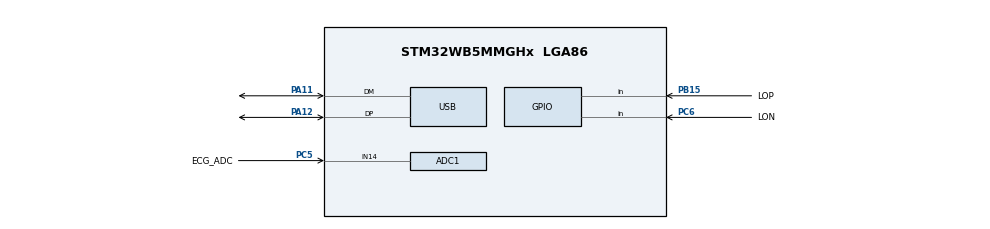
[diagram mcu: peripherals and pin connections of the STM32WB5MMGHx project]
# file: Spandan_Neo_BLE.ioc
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ADC1.Channel-5\#ChannelRegularConversion=ADC_CHANNEL_14
ADC1.NbrOfConversionFlag=1
ADC1.OffsetNumber-5\#ChannelRegularConversion=ADC_OFFSET_NONE
ADC1.Rank-5\#ChannelRegularConversion=1
ADC1.SamplingTime-5\#ChannelRegularConversion=ADC_SAMPLETIME_2CYCLES_5
ADC1.master=1
Mcu.Family=STM32WB
Mcu.Name=STM32WB5MMGHx
Mcu.Package=LGA86
NVIC.HSEM_IRQn=true\:0\:0\:false\:false\:true\:false\:true\:true
NVIC.IPCC_C1_RX_IRQn=true\:0\:0\:false\:false\:true\:true\:true\:true
NVIC.IPCC_C1_TX_IRQn=true\:0\:0\:false\:false\:true\:true\:true\:true
NVIC.PriorityGroup=NVIC_PRIORITYGROUP_4
NVIC.RTC_WKUP_IRQn=true\:0\:0\:false\:false\:true\:true\:true\:true
NVIC.TIM1_UP_TIM16_IRQn=true\:0\:0\:false\:false\:true\:true\:true\:true
NVIC.USB_LP_IRQn=true\:0\:0\:false\:false\:true\:false\:true\:true
PA11.Mode=Device
PA11.Signal=USB_DM
PA12.Mode=Device
PA12.Signal=USB_DP
PA13.Mode=Serial_Wire
PA13.Signal=SYS_JTMS-SWDIO
PA14.Mode=Serial_Wire
PA14.Signal=SYS_JTCK-SWCLK
PB15.GPIO_Label=LOP
PB15.Signal=GPIO_Input
PC5.GPIO_Label=ECG_ADC
PC5.Signal=ADCx_IN14
PC6.GPIO_Label=LON
PC6.Signal=GPIO_Input
ProjectManager.HeapSize=0x400
ProjectManager.StackSize=0x400
ProjectManager.TargetToolchain=STM32CubeIDE
RCC.ADCFreq_Value=48000000
RCC.AHB2CLKDivider=RCC_SYSCLK_DIV2
RCC.AHBFreq_Value=64000000
RCC.APB1Freq_Value=64000000
RCC.APB1TimFreq_Value=64000000
RCC.APB2Freq_Value=64000000
RCC.APB2TimFreq_Value=64000000
RCC.APB3Freq_Value=16000000
RCC.Cortex2_Div=SYSTICK_CLKSOURCE_HCLK_DIV8
RCC.CortexFreq_Value=64000000
RCC.HCLKFreq_Value=64000000
RCC.HSE_VALUE=32000000
RCC.HSI48_VALUE=48000000
RCC.HSI_VALUE=16000000
RCC.PLLN=32
RCC.PLLSAI1N=24
RCC.RTCClockSelection=RCC_RTCCLKSOURCE_LSE
RCC.SYSCLKFreq_VALUE=64000000
RCC.SYSCLKSource=RCC_SYSCLKSOURCE_PLLCLK
RCC.USBFreq_Value=48000000
RCC.VCOOutputFreq_Value=128000000
SH.ADCx_IN14.0=ADC1_IN14,IN14-Single-Ended
STM32_WPAN.CFG_GAP_DEVICE_NAME=SPANDAN_PATCH
STM32_WPAN.CFG_GAP_DEVICE_NAME_LENGTH=13
STM32_WPAN.CUSTOM_P2P_SERVER=Disabled
STM32_WPAN.CUSTOM_TEMPLATE=Enabled
STM32_WPAN.INCLUDE_AD_TYPE_COMPLETE_LOCAL_NAME=1
STM32_WPAN.NUMBER_OF_SERVICES=1
STM32_WPAN.SERVICE1_CHAR1_GATT_NOTIFY_READ_REQ_AND_WAIT_FOR_APPL_RESP=\ 
STM32_WPAN.SERVICE1_CHAR1_GATT_NOTIFY_WRITE_REQ_AND_WAIT_FOR_APPL_RESP=\ 
STM32_WPAN.SERVICE1_CHAR1_LENGTH_CHARACTERISTIC=CHAR_VALUE_LEN_VARIABLE
STM32_WPAN.SERVICE1_CHAR1_LONG_NAME=CHAR_WR
STM32_WPAN.SERVICE1_CHAR1_PROP_WRITE=CHAR_PROP_WRITE
STM32_WPAN.SERVICE1_CHAR1_SHORT_NAME=CHAR_WR
STM32_WPAN.SERVICE1_CHAR2_LENGTH_CHARACTERISTIC=CHAR_VALUE_LEN_VARIABLE
STM32_WPAN.SERVICE1_CHAR2_LONG_NAME=myCharNotify
STM32_WPAN.SERVICE1_CHAR2_PROP_NOTIFY=CHAR_PROP_NOTIFY
STM32_WPAN.SERVICE1_CHAR2_SHORT_NAME=myCharNotify
STM32_WPAN.SERVICE1_LONG_NAME=SPANDAN_PATCH
STM32_WPAN.SERVICE1_NUMBER_OF_CHARACTERISTICS=2
STM32_WPAN.SERVICE1_SHORT_NAME=SPANDAN_PATCH
USB_DEVICE.CLASS_NAME_FS=CDC
USB_DEVICE.VirtualMode=Cdc
USB_DEVICE.VirtualModeFS=Cdc_FS
VP_HSEM_VS_HSEM.Mode=HSEM_Activate
VP_IPCC_VS_IPCC.Mode=IPCC_Activate
VP_MEMORYMAP_VS_MEMORYMAP.Mode=CurAppReg
VP_RCC_V_OSC32_IN.Mode=LSE-External-Clock-Source
VP_RCC_V_OSC_IN.Mode=HSE-External-Clock-Source
VP_RF_VS_RF.Mode=RF_Activate
VP_RTC_VS_RTC_Activate.Mode=RTC_Enabled
VP_RTC_VS_RTC_Calendar.Mode=RTC_Calendar
VP_RTC_VS_RTC_WakeUp_intern.Mode=WakeUp
VP_SEQUENCER_VS_SEQUENCER.Mode=SEQUENCER_Enabled
VP_STM32_WPAN_VS_BLE_HOST.Mode=STM32_WPAN_Enabled
VP_TIM16_VS_ClockSourceINT.Mode=Enable_Timer
VP_TINY_LPM_VS_TINY_LPM.Mode=TINY_LPM_Enabled
VP_USB_DEVICE_VS_USB_DEVICE_CDC_FS.Mode=CDC_FS
board=STM32WB5MM-DK

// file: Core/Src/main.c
/* USER CODE BEGIN Header */
/**
  ******************************************************************************
  * @file           : main.c
  * @brief          : Main program body
  ******************************************************************************
  * @attention
  *
  * Copyright (c) 2026 STMicroelectronics.
  * All rights reserved.
  *
  * This software is licensed under terms that can be found in the LICENSE file
  * in the root directory of this software component.
  * If no LICENSE file comes with this software, it is provided AS-IS.
  *
  ******************************************************************************
  */
/* USER CODE END Header */
#include "main.h"
#include "adc.h"
#include "ipcc.h"
#include "rf.h"
#include "rtc.h"
#include "tim.h"
#include "usb_device.h"
#include "gpio.h"

/* USER CODE BEGIN PV */
extern void Main_task(void);
extern void Main_Init(void);
/* USER CODE END PV */

void SystemClock_Config(void);
void PeriphCommonClock_Config(void);

int main(void)
{

  /* MCU Configuration--------------------------------------------------------*/

  /* Reset of all peripherals, Initializes the Flash interface and the Systick. */

	HAL_Init();
  /* Config code for STM32_WPAN (HSE Tuning must be done before system clock configuration) */
  MX_APPE_Config();

  /* Configure the system clock */
  SystemClock_Config();

  /* Configure the peripherals common clocks */
  PeriphCommonClock_Config();

  /* IPCC initialisation */
  MX_IPCC_Init();

  /* Initialize all configured peripherals */
  MX_GPIO_Init();
  MX_ADC1_Init();
  MX_RTC_Init();
  MX_USB_Device_Init();
  MX_TIM16_Init();
  MX_RF_Init();
  /* USER CODE BEGIN 2 */
  Main_Init();

	#ifdef USB_Mode_Active

	  Main_task();

	#endif

  /* USER CODE END 2 */

  /* Init code for STM32_WPAN */
  MX_APPE_Init();

  /* Infinite loop */
  while (1)
  {
    MX_APPE_Process();

  }
}

void SystemClock_Config(void)
{
  RCC_OscInitTypeDef RCC_OscInitStruct = {0};
  RCC_ClkInitTypeDef RCC_ClkInitStruct = {0};

  /** Configure LSE Drive Capability
  */
  HAL_PWR_EnableBkUpAccess();
  __HAL_RCC_LSEDRIVE_CONFIG(RCC_LSEDRIVE_MEDIUMHIGH);

  /** Configure the main internal regulator output voltage
  */
  __HAL_PWR_VOLTAGESCALING_CONFIG(PWR_REGULATOR_VOLTAGE_SCALE1);

  /** Initializes the RCC Oscillators according to the specified parameters
  * in the RCC_OscInitTypeDef structure.
  */
  RCC_OscInitStruct.OscillatorType = RCC_OSCILLATORTYPE_HSI|RCC_OSCILLATORTYPE_HSE
                              |RCC_OSCILLATORTYPE_LSE|RCC_OSCILLATORTYPE_MSI;
  RCC_OscInitStruct.HSEState = RCC_HSE_ON;
  RCC_OscInitStruct.LSEState = RCC_LSE_ON;
  RCC_OscInitStruct.HSIState = RCC_HSI_ON;
  RCC_OscInitStruct.MSIState = RCC_MSI_ON;
  RCC_OscInitStruct.HSICalibrationValue = RCC_HSICALIBRATION_DEFAULT;
  RCC_OscInitStruct.MSICalibrationValue = RCC_MSICALIBRATION_DEFAULT;
  RCC_OscInitStruct.MSIClockRange = RCC_MSIRANGE_6;
  RCC_OscInitStruct.PLL.PLLState = RCC_PLL_ON;
  RCC_OscInitStruct.PLL.PLLSource = RCC_PLLSOURCE_MSI;
  RCC_OscInitStruct.PLL.PLLM = RCC_PLLM_DIV1;
  RCC_OscInitStruct.PLL.PLLN = 32;
  RCC_OscInitStruct.PLL.PLLP = RCC_PLLP_DIV2;
  RCC_OscInitStruct.PLL.PLLR = RCC_PLLR_DIV2;
  RCC_OscInitStruct.PLL.PLLQ = RCC_PLLQ_DIV2;
  if (HAL_RCC_OscConfig(&RCC_OscInitStruct) != HAL_OK)
  {
    Error_Handler();
  }

  /** Configure the SYSCLKSource, HCLK, PCLK1 and PCLK2 clocks dividers
  */
  RCC_ClkInitStruct.ClockType = RCC_CLOCKTYPE_HCLK4|RCC_CLOCKTYPE_HCLK2
                              |RCC_CLOCKTYPE_HCLK|RCC_CLOCKTYPE_SYSCLK
                              |RCC_CLOCKTYPE_PCLK1|RCC_CLOCKTYPE_PCLK2;
  RCC_ClkInitStruct.SYSCLKSource = RCC_SYSCLKSOURCE_PLLCLK;
  RCC_ClkInitStruct.AHBCLKDivider = RCC_SYSCLK_DIV1;
  RCC_ClkInitStruct.APB1CLKDivider = RCC_HCLK_DIV1;
  RCC_ClkInitStruct.APB2CLKDivider = RCC_HCLK_DIV1;
  RCC_ClkInitStruct.AHBCLK2Divider = RCC_SYSCLK_DIV2;
  RCC_ClkInitStruct.AHBCLK4Divider = RCC_SYSCLK_DIV1;

  if (HAL_RCC_ClockConfig(&RCC_ClkInitStruct, FLASH_LATENCY_3) != HAL_OK)
  {
    Error_Handler();
  }

  /** Enable MSI Auto calibration
  */
  HAL_RCCEx_EnableMSIPLLMode();
}

void PeriphCommonClock_Config(void)
{
  RCC_PeriphCLKInitTypeDef PeriphClkInitStruct = {0};

  /** Initializes the peripherals clock
  */
  PeriphClkInitStruct.PeriphClockSelection = RCC_PERIPHCLK_SMPS|RCC_PERIPHCLK_RFWAKEUP
                              |RCC_PERIPHCLK_USB|RCC_PERIPHCLK_ADC;
  PeriphClkInitStruct.PLLSAI1.PLLN = 24;
  PeriphClkInitStruct.PLLSAI1.PLLP = RCC_PLLP_DIV2;
  PeriphClkInitStruct.PLLSAI1.PLLQ = RCC_PLLQ_DIV2;
  PeriphClkInitStruct.PLLSAI1.PLLR = RCC_PLLR_DIV2;
  PeriphClkInitStruct.PLLSAI1.PLLSAI1ClockOut = RCC_PLLSAI1_USBCLK|RCC_PLLSAI1_ADCCLK;
  PeriphClkInitStruct.UsbClockSelection = RCC_USBCLKSOURCE_PLLSAI1;
  PeriphClkInitStruct.AdcClockSelection = RCC_ADCCLKSOURCE_PLLSAI1;
  PeriphClkInitStruct.RFWakeUpClockSelection = RCC_RFWKPCLKSOURCE_HSE_DIV1024;
  PeriphClkInitStruct.SmpsClockSelection = RCC_SMPSCLKSOURCE_HSI;
  PeriphClkInitStruct.SmpsDivSelection = RCC_SMPSCLKDIV_RANGE1;

  if (HAL_RCCEx_PeriphCLKConfig(&PeriphClkInitStruct) != HAL_OK)
  {
    Error_Handler();
  }
}

void Error_Handler(void)
{
  __disable_irq();
  while (1)
  {
  }
}
